# V32F20x_CM33 register map
File version: 1.0.3
CPU: CM33 r0p4, little endian, MPU, FPU, DSP, 3 interrupt priority bits, 8 SAU regions
Registers are 32-bit, read-write, reset 0x0 unless marked. A register's access mark holds for its fields unless they carry their own. Offsets are from the block's base; [hi:lo] are bit positions; {n}, {i} and the like mark numbered series.

## ENCENG — ENCENG Peripheral Interface
Base 0x40206000
Same registers: SEC_ENCENG 0x50206000
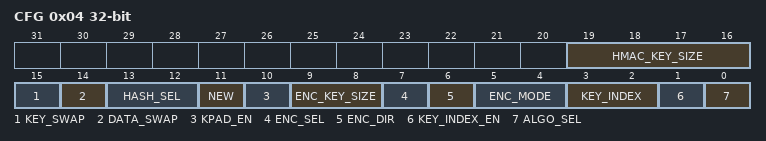
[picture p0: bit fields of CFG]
0x04 CFG — ENCENG configuration register.
  [19:16] HMAC_KEY_SIZE — The key size of HMAC, unit in word:
  [15] KEY_SWAP — If 1 will swap the key input bytes in each word The default is byte order so LSB is 1st order but allows swapping to MSB is first
  [14] DATA_SWAP — If 1 will swap bytes in the word for hash and encryption The default is byte order so LSB is 1st order but allows swapping to MSB is first
  [13:12] HASH_SEL — Hash algorithm select:
  [11] NEW — When this bit is set indicate there will issue a new encryption or hash in following operation
  [10] KPAD_EN — Whether to enable the IPAD and OPAD in HMAC
  [9:8] ENC_KEY_SIZE — The size of Encryption Key:
  [7] ENC_SEL — Select the encryption algorithm:
  [6] ENC_DIR — Encrypt or decrypt select:
  [5:4] ENC_MODE — Encryption or decryption mode:
  [3:2] KEY_INDEX — The key index:
  [1] KEY_INDEX_EN — Using the key through the index:
  [0] ALGO_SEL — Encryption or hash algorithm select:
0x08 CMD — ENCENG command register.
  [0] START — Start bit write 1 to this bit will issue the engine start
0x10 SRCLEN — Source data length register.
  [31:0] LEN — Length register, unit in bytes.
0x14 SRCADDR — Source data address register.
  [31:0] SADDR — Source data address for processing.
0x18 DSTADDR — Destination data address register.
  [31:0] RADDR — Result data address.
0x20 INTMASK — ENCENG interrupt mask register.
  [0] CMD_DONE_MASK — Command done interrupt mask
0x24 INTSTS — ENCENG interrupt status register.
  [0] CMD_DONE — Command has been finished.
{0x30+4i} K{i:02} (i=0..7) — ENCENG key 0 section {i} register.
  [31:0] KEY{i:02} — The section {i} of key 0
{0x28+4i} K{i} (i=10..17) — ENCENG key 1 section {i-10} register.
  [31:0] KEY{i} — The section {i-10} of key 1
{0x20+4i} K{i} (i=20..27) — ENCENG key 2 section {i-20} register.
  [31:0] KEY{i} — The section {i-20} of key 2
{0x18+4i} K{i} (i=30..37) — ENCENG key 3 section {i-30} register.
  [31:0] KEY{i} — The section {i-30} of key 3

## RETRAM — RETRAM Peripheral Interface
Base 0x40100000
Same registers: SEC_RETRAM 0x50100000
{0x0+4i} RAM{i} (i=0..63) — PMU 32 bits Retention RAM 0~63
  [31:0] RAM — There is a 256 bytes 64x32 SRAM embedded in the PMU controller

## COMP — COMP Peripheral Interface
Base 0x40101800
Same registers: SEC_COMP 0x50101800
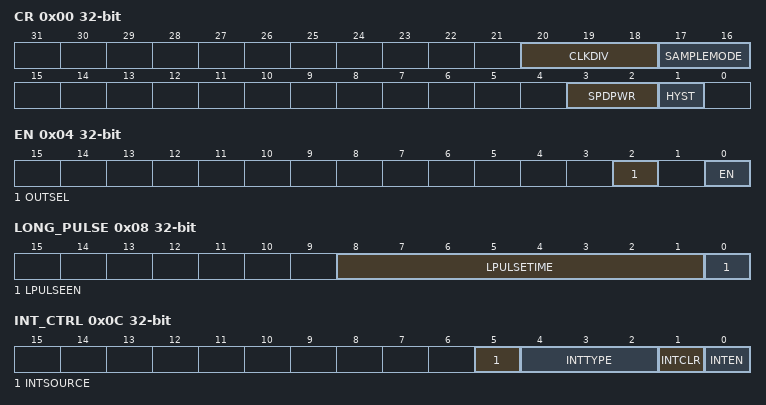
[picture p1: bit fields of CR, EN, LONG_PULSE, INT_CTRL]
0x00 CR — Control Register
  [20:18] CLKDIV — Filter clock divider
  [17:16] SAMPLEMODE — Control the filtering of the Analog Comparator output
  [3:2] SPDPWR — 00 Low speed Ultra low power Power consumption 2
  [1] HYST — 0: No Hysteresis Voltage
0x04 EN — Enable Register
  [2] OUTSEL — Comparator comparison select
  [0] EN — Enable Comparator
0x08 LONG_PULSE — Long pulse mode register
  [8:1] LPULSETIME — Desired time period of the long pulse.
  [0] LPULSEEN — Enable long pulse mode
0x0C INT_CTRL — Interrupt Control
  [5] INTSOURCE — Select which Analog comparator output filtered or unfiltered is used for interrupt detection
  [4:2] INTTYPE — Comparator interrupt type selector.
  [1] INTCLR — COMP interrupt clear.
  [0] INTEN — COMP interrupt enable.
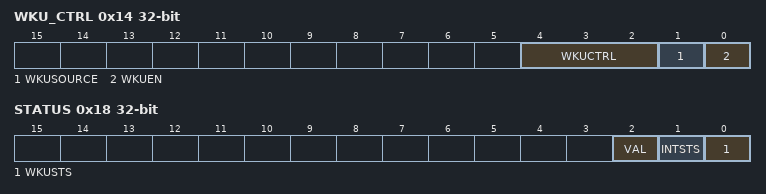
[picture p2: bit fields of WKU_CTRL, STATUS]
0x14 WKU_CTRL — Wake up control
  [4:2] WKUCTRL — Comparator wake up type selector.
  [1] WKUSOURCE — Select which Analog comparator output filtered our unfiltered is used for wake up detection
  [0] WKUEN — 1: Wake Up enable
0x18 STATUS
  [2] VAL — Comparator Output
  [1] INTSTS — Interrupt Status
  [0] WKUSTS — Wake-Up Status

## GPIOA — GPIOA Peripheral Interface
Base 0x40104000
Same registers: GPIOB 0x40104400, GPIOC 0x40104800, GPIOD 0x40104C00, GPIOE 0x40105000, GPIOF 0x40105400, GPIOG 0x40105800, GPIOH 0x40105C00, GPIOI 0x40106000, SEC_GPIOA 0x50104000, SEC_GPIOB 0x50104400, SEC_GPIOC 0x50104800, SEC_GPIOD 0x50104C00, SEC_GPIOE 0x50105000, SEC_GPIOF 0x50105400, SEC_GPIOG 0x50105800, SEC_GPIOH 0x50105C00, SEC_GPIOI 0x50106000
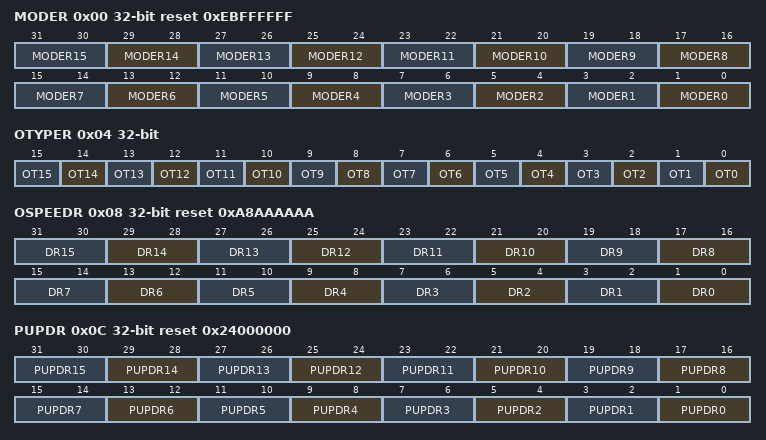
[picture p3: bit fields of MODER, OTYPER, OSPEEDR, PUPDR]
0x00 MODER reset 0xEBFFFFFF — GPIOx port mode register
  [2n+1:2n] MODER{n} (n=0..15) — These bits are written by software to configure the Px{n} direction mode
0x04 OTYPER — GPIO_OTYPER Abstract
  [n] OT{n} (n=0..15) — These bits are written by software to configure the output type of the Px{n} port
0x08 OSPEEDR reset 0xA8AAAAAA — GPIOx output drive strength
  [2n+1:2n] DR{n} (n=0..15) — Px{n} output drive strength
0x0C PUPDR reset 0x24000000 — GPIOx port pull-up and pull-down register
  [2n+1:2n] PUPDR{n} (n=0..15) — These bits are written by software to configure the Px{n} pull up or pull down
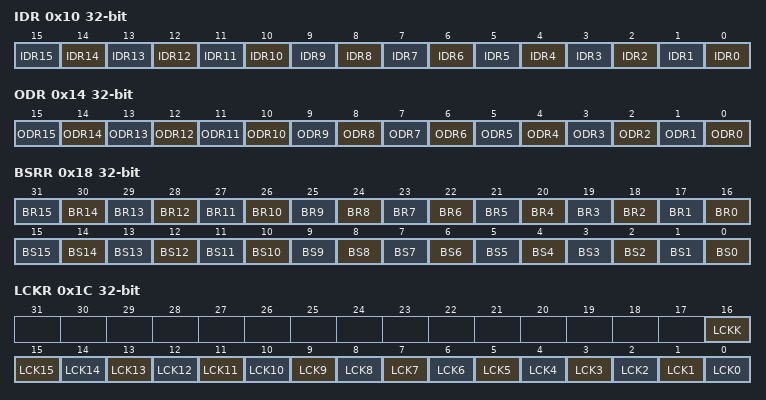
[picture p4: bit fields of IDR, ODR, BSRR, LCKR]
0x10 IDR ro — GPIOx port input data register
  [n] IDR{n} (n=0..15) — These bits are read only and can be accessed in word mode only
0x14 ODR — GPIOx port output data register
  [n] ODR{n} (n=0..15) — These bits can be read and written by software for Px{n}
0x18 BSRR — GPIOx port bit set/reset register
  [n+16] BR{n} (n=0..15) — This bit is write only
  [n] BS{n} (n=0..15) — This bit is write only
0x1C LCKR — GPIO_LCKR Abstract
  [16] LCKK — This bit can be read any time
  [n] LCK{n} (n=0..15) — Px{n} configure lock signal
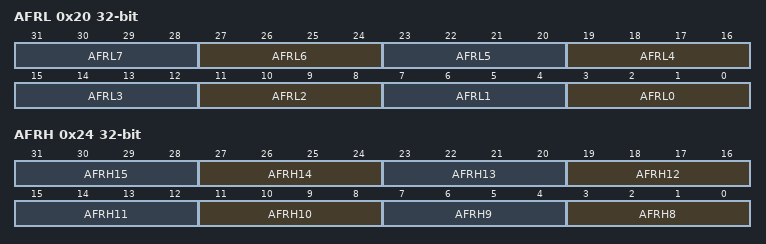
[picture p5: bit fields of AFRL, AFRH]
0x20 AFRL — Px0 to Px7 Alternate function selection
  [4n+3:4n] AFRL{n} (n=0..7) — Px{n} Alternate function selection
0x24 AFRH — Px8 to Px15 Alternate function selection
  [4n-29:4n-32] AFRH{n} (n=8..15) — Px{n} Alternate function selection
